AUTOSAR XML (schema 4-3-0)
package /ComponentTypes
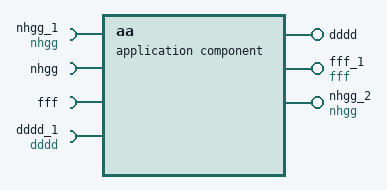
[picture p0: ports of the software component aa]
  application sw component type aa
    provide port dddd: provided-com-specs=[Element_1, Element], provided-interface=dddd
    provide port fff_1: provided-com-specs=[Element_1, Element], provided-interface=fff
    4 x require port:
      nhgg_1: required-com-specs=[rrth, hjn, Operation], required-interface=nhgg
      nhgg: required-com-specs=[rrth, hjn, Operation], required-interface=nhgg
      fff: required-interface=fff
        required-com-specs:
          data-element=Element_1, filter=data-filter-type=ALWAYS
          data-element=Element, filter=data-filter-type=ALWAYS
      dddd_1: required-interface=dddd
        required-com-specs:
          data-element=Element_1, filter=data-filter-type=ALWAYS
          data-element=Element, filter=data-filter-type=ALWAYS
    provide port nhgg_2: provided-com-specs=[{operation=rrth, queue-length=1}, {operation=hjn, queue-length=1}, {operation=Operation, queue-length=1}], provided-interface=nhgg
    behavior aa_InternalBehavior
  swc implementation aa_Implementation: behavior=aa_InternalBehavior
